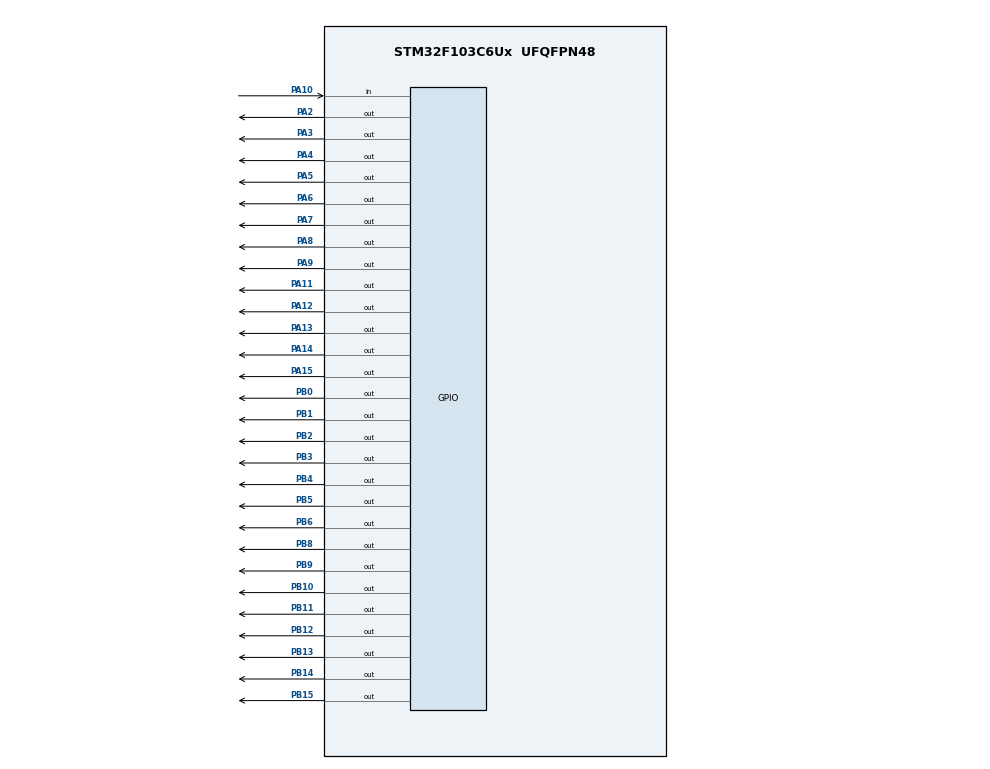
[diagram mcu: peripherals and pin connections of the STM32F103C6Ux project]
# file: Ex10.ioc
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Mcu.Family=STM32F1
Mcu.Name=STM32F103C6Ux
Mcu.Package=UFQFPN48
NVIC.PriorityGroup=NVIC_PRIORITYGROUP_4
NVIC.TIM2_IRQn=true\:0\:0\:false\:false\:true\:true\:true
PA10.Signal=GPIO_Input
PA11.Signal=GPIO_Output
PA12.Signal=GPIO_Output
PA13.Signal=GPIO_Output
PA14.Signal=GPIO_Output
PA15.Signal=GPIO_Output
PA2.Signal=GPIO_Output
PA3.Signal=GPIO_Output
PA4.Signal=GPIO_Output
PA5.Signal=GPIO_Output
PA6.PinState=GPIO_PIN_RESET
PA6.Signal=GPIO_Output
PA7.Signal=GPIO_Output
PA8.Signal=GPIO_Output
PA9.Signal=GPIO_Output
PB0.Signal=GPIO_Output
PB1.Signal=GPIO_Output
PB10.Signal=GPIO_Output
PB11.Signal=GPIO_Output
PB12.Signal=GPIO_Output
PB13.Signal=GPIO_Output
PB14.Signal=GPIO_Output
PB15.Signal=GPIO_Output
PB2.Signal=GPIO_Output
PB3.Signal=GPIO_Output
PB4.Signal=GPIO_Output
PB5.Signal=GPIO_Output
PB6.Signal=GPIO_Output
PB8.Signal=GPIO_Output
PB9.Signal=GPIO_Output
ProjectManager.HeapSize=0x200
ProjectManager.StackSize=0x400
ProjectManager.TargetToolchain=STM32CubeIDE
RCC.APB1Freq_Value=8000000
RCC.APB2Freq_Value=8000000
TIM2.Period=9
TIM2.Prescaler=7999
VP_SYS_VS_ND.Mode=No_Debug
VP_TIM2_VS_ClockSourceINT.Mode=Internal
board=custom

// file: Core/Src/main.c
/* USER CODE BEGIN Header */
/**
  ******************************************************************************
  * @file           : main.c
  * @brief          : Main program body
  ******************************************************************************
  */
/* USER CODE END Header */
#include "main.h"

TIM_HandleTypeDef htim2;

void SystemClock_Config(void);
static void MX_GPIO_Init(void);
static void MX_TIM2_Init(void);

/* USER CODE BEGIN 0 */
#define MAX_LED 4
#define MAX_LED_MATRIX 8
#define TIMER_CYCLE 10

// --- LED 7 đoạn ---
int index_led = 0;
int led_buffer[MAX_LED] = {0, 0, 0, 0};
uint8_t message[16] = {
    // Ký tự 'A' (8 cột)
    0x00, 0x7C, 0x12, 0x11, 0x12, 0x7C, 0x00, 0x00,
    // Ký tự 'B' (8 cột)
    0x00, 0x7F, 0x49, 0x49, 0x49, 0x36, 0x00, 0x00
};
int scroll_offset = 0;

// --- Đồng hồ ---
int hour = 15;
int minute = 8;
int second = 50;
int dot_state = 0;

// --- Software Timer 0 (đồng hồ 1s) ---
int timer0_counter = 0;
int timer0_flag = 0;
void setTimer0(int duration) {
    timer0_counter = duration / TIMER_CYCLE;
    timer0_flag = 0;
}
void timer0_run() {
    if (timer0_counter > 0) {
        timer0_counter--;
        if (timer0_counter == 0) timer0_flag = 1;
    }
}

// --- Software Timer 1 (quét LED 7 đoạn 250ms) ---
int timer1_counter = 0;
int timer1_flag = 0;
void setTimer1(int duration) {
    timer1_counter = duration / TIMER_CYCLE;
    timer1_flag = 0;
}
void timer1_run() {
    if (timer1_counter > 0) {
        timer1_counter--;
        if (timer1_counter == 0) timer1_flag = 1;
    }
}

// --- Software Timer 2 (quét LED Matrix 5ms) ---
int timer2_counter = 0;
int timer2_flag = 0;
void setTimer2(int duration) {
    timer2_counter = duration / TIMER_CYCLE;
    timer2_flag = 0;
}
void timer2_run() {
    if (timer2_counter > 0) {
        timer2_counter--;
        if (timer2_counter == 0) timer2_flag = 1;
    }
}

// --- Mã hiển thị LED 7 đoạn (Common Anode) ---
const int seg_code[10] = {
    0x40, 0x79, 0x24, 0x30, 0x19,
    0x12, 0x02, 0x78, 0x00, 0x10
};

void display7SEG(int num) {
    if (num < 0 || num > 9) return;
    uint16_t temp = GPIOB->ODR;
    temp &= 0xFF80;
    temp |= (seg_code[num] & 0x7F);
    GPIOB->ODR = temp;
}

void update7SEG(int index) {
    HAL_GPIO_WritePin(GPIOA, GPIO_PIN_6, GPIO_PIN_SET);
    HAL_GPIO_WritePin(GPIOA, GPIO_PIN_7, GPIO_PIN_SET);
    HAL_GPIO_WritePin(GPIOA, GPIO_PIN_8, GPIO_PIN_SET);
    HAL_GPIO_WritePin(GPIOA, GPIO_PIN_9, GPIO_PIN_SET);

    switch (index) {
        case 0: HAL_GPIO_WritePin(GPIOA, GPIO_PIN_6, GPIO_PIN_RESET); display7SEG(led_buffer[0]); break;
        case 1: HAL_GPIO_WritePin(GPIOA, GPIO_PIN_7, GPIO_PIN_RESET); display7SEG(led_buffer[1]); break;
        case 2: HAL_GPIO_WritePin(GPIOA, GPIO_PIN_8, GPIO_PIN_RESET); display7SEG(led_buffer[2]); break;
        case 3: HAL_GPIO_WritePin(GPIOA, GPIO_PIN_9, GPIO_PIN_RESET); display7SEG(led_buffer[3]); break;
    }
}

void updateClockBuffer() {
    led_buffer[0] = hour / 10;
    led_buffer[1] = hour % 10;
    led_buffer[2] = minute / 10;
    led_buffer[3] = minute % 10;
}

// --- LED MATRIX ---
int index_led_matrix = 0;
uint8_t matrix_buffer[8] = {0x00, 0x00, 0x00, 0x00, 0x00, 0x00, 0x00, 0x00};

uint8_t character_A[8] = {
    0x00, 0x7C, 0x12, 0x11, 0x12, 0x7C, 0x00, 0x00
};

// Hàm quét LED Matrix
// ENM0->PA1, ENM1->PA2, ENM2->PA10, ENM3->PA11
// ENM4->PA12, ENM5->PA13, ENM6->PA14, ENM7->PA15
void updateLEDMatrix(int index) {
    // Bước 1: Tắt tất cả cột
	uint8_t data = message[(scroll_offset + index) % 16];

	    // Bước 1: Tắt tất cả cột
	    HAL_GPIO_WritePin(GPIOA, GPIO_PIN_2 | GPIO_PIN_3 | GPIO_PIN_10 | GPIO_PIN_11 |
	                             GPIO_PIN_12 | GPIO_PIN_13 | GPIO_PIN_14 | GPIO_PIN_15,
	                      GPIO_PIN_RESET);

	    // Bước 2: Xuất dữ liệu hàng cho cột hiện tại (PB8 -> PB15)
	    GPIOB->ODR = (GPIOB->ODR & 0x00FF) | ((uint16_t)data << 8);

	    // Bước 3: Bật cột tương ứng (ENM0 -> PA2, ENM1 -> PA3, ...)
	    switch (index) {
	        case 0: HAL_GPIO_WritePin(GPIOA, GPIO_PIN_2,  GPIO_PIN_SET); break;
	        case 1: HAL_GPIO_WritePin(GPIOA, GPIO_PIN_3,  GPIO_PIN_SET); break;
	        case 2: HAL_GPIO_WritePin(GPIOA, GPIO_PIN_10, GPIO_PIN_SET); break;
	        case 3: HAL_GPIO_WritePin(GPIOA, GPIO_PIN_11, GPIO_PIN_SET); break;
	        case 4: HAL_GPIO_WritePin(GPIOA, GPIO_PIN_12, GPIO_PIN_SET); break;
	        case 5: HAL_GPIO_WritePin(GPIOA, GPIO_PIN_13, GPIO_PIN_SET); break;
	        case 6: HAL_GPIO_WritePin(GPIOA, GPIO_PIN_14, GPIO_PIN_SET); break;
	        case 7: HAL_GPIO_WritePin(GPIOA, GPIO_PIN_15, GPIO_PIN_SET); break;
	    }
}
int timer3_counter = 0;
int timer3_flag = 0;
void setTimer3(int duration) {
    timer3_counter = duration / TIMER_CYCLE;
    timer3_flag = 0;
}
void timer3_run() {
    if (timer3_counter > 0) {
        timer3_counter--;
        if (timer3_counter == 0) timer3_flag = 1;
    }
}
/* USER CODE END 0 */

int main(void)
{
  HAL_Init();
  SystemClock_Config();
  MX_GPIO_Init();
  MX_TIM2_Init();

  /* USER CODE BEGIN 2 */
  HAL_TIM_Base_Start_IT(&htim2);

  for (int i = 0; i < 8; i++) {
      matrix_buffer[i] = character_A[i];
  }

  updateClockBuffer();
  setTimer0(1000);
  setTimer1(250);
  setTimer2(10);
  setTimer3(200);
  /* USER CODE END 2 */

  while (1)
  {
    /* USER CODE BEGIN 3 */
    // ===== TIMER 0: Đồng hồ + DOT =====
    if (timer0_flag == 1) {
        timer0_flag = 0;

        second++;
        if (second >= 60) { second = 0; minute++; }
        if (minute >= 60) { minute = 0; hour++; }
        if (hour >= 24) { hour = 0; }
        updateClockBuffer();

        // Nhấp nháy DOT (PA3)
        dot_state = !dot_state;
        HAL_GPIO_WritePin(GPIOA, GPIO_PIN_4, dot_state ? GPIO_PIN_SET : GPIO_PIN_RESET);

        setTimer0(1000);
    }

    // ===== TIMER 1: Quét LED 7 đoạn =====
    if (timer1_flag == 1) {
        timer1_flag = 0;
        update7SEG(index_led);
        index_led++;
        if (index_led >= MAX_LED) index_led = 0;
        setTimer1(250);
    }

    // ===== TIMER 2: Quét LED Matrix =====
    if (timer2_flag == 1) {
        timer2_flag = 0;
        updateLEDMatrix(index_led_matrix);
        index_led_matrix++;
        if (index_led_matrix >= MAX_LED_MATRIX) index_led_matrix = 0;
        setTimer2(10);
    }
    if (timer3_flag == 1) {
        timer3_flag = 0;
        scroll_offset++;
        if (scroll_offset >= 16) scroll_offset = 0;   // Quay vòng
        setTimer3(200);
    }
    /* USER CODE END 3 */
  }
}

void SystemClock_Config(void)
{
  RCC_OscInitTypeDef RCC_OscInitStruct = {0};
  RCC_ClkInitTypeDef RCC_ClkInitStruct = {0};

  RCC_OscInitStruct.OscillatorType = RCC_OSCILLATORTYPE_HSI;
  RCC_OscInitStruct.HSIState = RCC_HSI_ON;
  RCC_OscInitStruct.HSICalibrationValue = RCC_HSICALIBRATION_DEFAULT;
  RCC_OscInitStruct.PLL.PLLState = RCC_PLL_NONE;
  if (HAL_RCC_OscConfig(&RCC_OscInitStruct) != HAL_OK) Error_Handler();

  RCC_ClkInitStruct.ClockType = RCC_CLOCKTYPE_HCLK|RCC_CLOCKTYPE_SYSCLK
                              |RCC_CLOCKTYPE_PCLK1|RCC_CLOCKTYPE_PCLK2;
  RCC_ClkInitStruct.SYSCLKSource = RCC_SYSCLKSOURCE_HSI;
  RCC_ClkInitStruct.AHBCLKDivider = RCC_SYSCLK_DIV1;
  RCC_ClkInitStruct.APB1CLKDivider = RCC_HCLK_DIV1;
  RCC_ClkInitStruct.APB2CLKDivider = RCC_HCLK_DIV1;
  if (HAL_RCC_ClockConfig(&RCC_ClkInitStruct, FLASH_LATENCY_0) != HAL_OK) Error_Handler();
}

static void MX_TIM2_Init(void)
{
  TIM_ClockConfigTypeDef sClockSourceConfig = {0};
  TIM_MasterConfigTypeDef sMasterConfig = {0};

  htim2.Instance = TIM2;
  htim2.Init.Prescaler = 7999;
  htim2.Init.CounterMode = TIM_COUNTERMODE_UP;
  htim2.Init.Period = 9;
  htim2.Init.ClockDivision = TIM_CLOCKDIVISION_DIV1;
  htim2.Init.AutoReloadPreload = TIM_AUTORELOAD_PRELOAD_DISABLE;
  if (HAL_TIM_Base_Init(&htim2) != HAL_OK) Error_Handler();
  sClockSourceConfig.ClockSource = TIM_CLOCKSOURCE_INTERNAL;
  if (HAL_TIM_ConfigClockSource(&htim2, &sClockSourceConfig) != HAL_OK) Error_Handler();
  sMasterConfig.MasterOutputTrigger = TIM_TRGO_RESET;
  sMasterConfig.MasterSlaveMode = TIM_MASTERSLAVEMODE_DISABLE;
  if (HAL_TIMEx_MasterConfigSynchronization(&htim2, &sMasterConfig) != HAL_OK) Error_Handler();
}

static void MX_GPIO_Init(void)
{
  GPIO_InitTypeDef GPIO_InitStruct = {0};

  __HAL_RCC_GPIOA_CLK_ENABLE();
  __HAL_RCC_GPIOB_CLK_ENABLE();

  HAL_GPIO_WritePin(GPIOA, GPIO_PIN_1|GPIO_PIN_2|GPIO_PIN_3|GPIO_PIN_4
                          |GPIO_PIN_5|GPIO_PIN_6|GPIO_PIN_7|GPIO_PIN_8
                          |GPIO_PIN_9|GPIO_PIN_10|GPIO_PIN_11|GPIO_PIN_12
                          |GPIO_PIN_13|GPIO_PIN_14|GPIO_PIN_15,
                    GPIO_PIN_RESET);
  HAL_GPIO_WritePin(GPIOB, GPIO_PIN_0|GPIO_PIN_1|GPIO_PIN_2|GPIO_PIN_3
                          |GPIO_PIN_4|GPIO_PIN_5|GPIO_PIN_6|GPIO_PIN_8
                          |GPIO_PIN_9|GPIO_PIN_10|GPIO_PIN_11|GPIO_PIN_12
                          |GPIO_PIN_13|GPIO_PIN_14|GPIO_PIN_15,
                    GPIO_PIN_RESET);

  // Cấu hình GPIOA output
  GPIO_InitStruct.Pin = GPIO_PIN_1|GPIO_PIN_2|GPIO_PIN_3|GPIO_PIN_4
                       |GPIO_PIN_5|GPIO_PIN_6|GPIO_PIN_7|GPIO_PIN_8
                       |GPIO_PIN_9|GPIO_PIN_10|GPIO_PIN_11|GPIO_PIN_12
                       |GPIO_PIN_13|GPIO_PIN_14|GPIO_PIN_15;
  GPIO_InitStruct.Mode = GPIO_MODE_OUTPUT_PP;
  GPIO_InitStruct.Pull = GPIO_NOPULL;
  GPIO_InitStruct.Speed = GPIO_SPEED_FREQ_LOW;
  HAL_GPIO_Init(GPIOA, &GPIO_InitStruct);

  // Cấu hình GPIOB
  GPIO_InitStruct.Pin = GPIO_PIN_0|GPIO_PIN_1|GPIO_PIN_2|GPIO_PIN_3
                       |GPIO_PIN_4|GPIO_PIN_5|GPIO_PIN_6|GPIO_PIN_8
                       |GPIO_PIN_9|GPIO_PIN_10|GPIO_PIN_11|GPIO_PIN_12
                       |GPIO_PIN_13|GPIO_PIN_14|GPIO_PIN_15;
  GPIO_InitStruct.Mode = GPIO_MODE_OUTPUT_PP;
  GPIO_InitStruct.Pull = GPIO_NOPULL;
  GPIO_InitStruct.Speed = GPIO_SPEED_FREQ_LOW;
  HAL_GPIO_Init(GPIOB, &GPIO_InitStruct);
}

/* USER CODE BEGIN 4 */
void HAL_TIM_PeriodElapsedCallback(TIM_HandleTypeDef *htim)
{
    if (htim->Instance == TIM2)
    {
        timer0_run();
        timer1_run();
        timer2_run();
        timer3_run();
    }
}
/* USER CODE END 4 */

void Error_Handler(void)
{
  __disable_irq();
  while (1) {}
}
